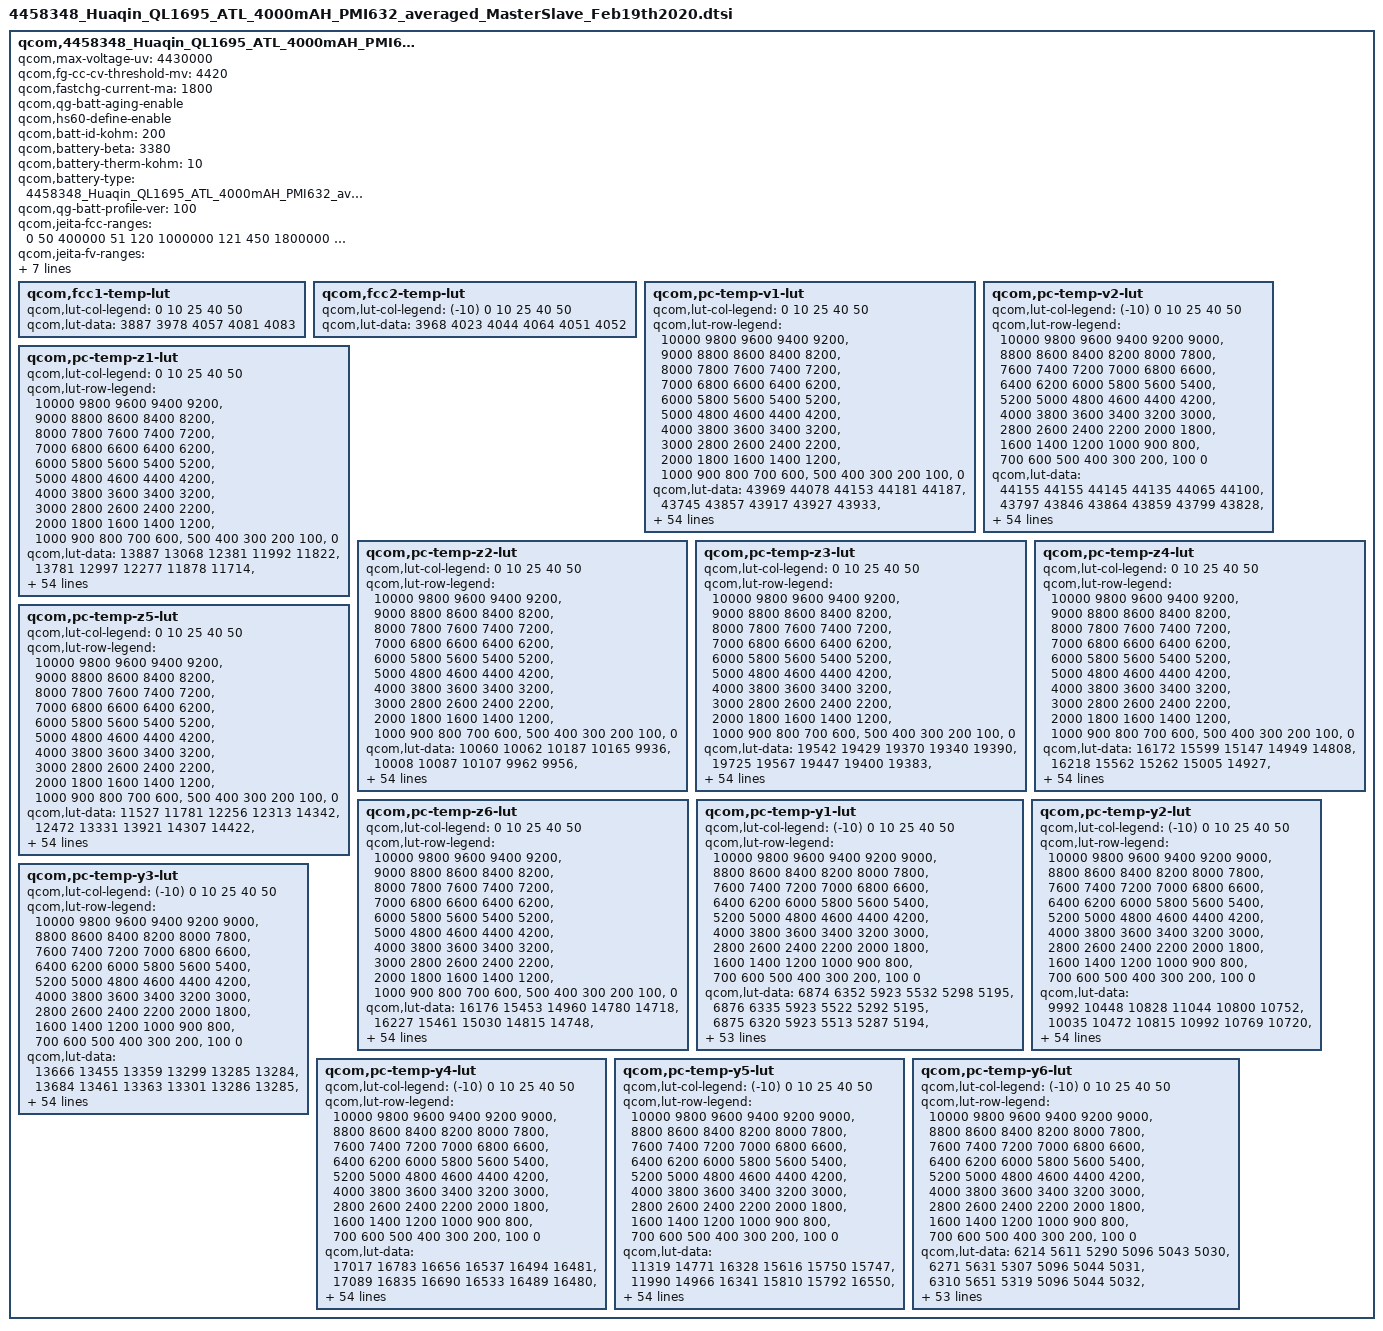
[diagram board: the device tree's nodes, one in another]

qcom,4458348_Huaqin_QL1695_ATL_4000mAH_PMI632 {
    /* 4458348_Huaqin_QL1695_ATL_4000mAH_PMI632_averaged_MasterSlave_Feb19th2020 */
    qcom,max-voltage-uv = <4430000>;
	qcom,fg-cc-cv-threshold-mv = <4420>;
	/* HS60 add for ZQL1693-60 Encrease FCC to 1800mA to trigger TA(5V/1.55A) more ICL by gaochao at 2019/11/05 start */
	qcom,fastchg-current-ma = <1800>;
	/* HS60 add for ZQL1693-60 Encrease FCC to 1800mA to trigger TA(5V/1.55A) more ICL by gaochao at 2019/11/05 end */
	/* HS60 add for SR-ZQL1695-01-357 Import battery aging by gaochao at 2019/08/29 start */
	qcom,qg-batt-aging-enable;
	/* HS60 add for SR-ZQL1695-01-357 Import battery aging by gaochao at 2019/08/29 end */
	/* HS70 add for HS70-135 Distinguish HS60 and HS70 charging by gaochao at 2019/10/03 start */
	qcom,hs60-define-enable;
	/* HS70 add for HS70-135 Distinguish HS60 and HS70 charging by gaochao at 2019/10/03 end */
	qcom,batt-id-kohm = <200>;
	qcom,battery-beta = <3380>;
    qcom,battery-therm-kohm = <10>;
    qcom,battery-type = "4458348_Huaqin_QL1695_ATL_4000mAH_PMI632_averaged_MasterSlave_Feb19th2020";
    qcom,qg-batt-profile-ver = <100>;
	/*HS60 add for ZQL1693-50 by wangzikang at 2019/09/26 start*/
	/*HS60 add for ZQL1693-58 by wangzikang at 2019/10/18 start*/
	/* HS60 add for ZQL1693-60 Encrease FCC to 1800mA to trigger TA(5V/1.55A) more ICL by gaochao at 2019/11/05 start */
	qcom,jeita-fcc-ranges = <0   50  400000
				 51   120   1000000
				 121 450  1800000
				 451 500  1800000>;
	/* HS60 add for ZQL1693-60 Encrease FCC to 1800mA to trigger TA(5V/1.55A) more ICL by gaochao at 2019/11/05 end */
	/*HS60 add for ZQL1693-58 by wangzikang at 2019/10/18 end*/
	qcom,jeita-fv-ranges =  <0   50  4430000
				 51   120  4430000
				 121 450  4430000
				 451 500  4200000>;
	/*HS60 add for ZQL1693-50 by wangzikang at 2019/09/26 end*/
	/* HS60 add for SR-ZQL1695-01-357 Import battery aging by gaochao at 2019/08/29 start */
	qcom,vfloat-ranges = <0 299 4430000
	                      300 399 4410000
                              400 699 4390000
                              700 999 4370000
                              1000 9999 4320000>;

	qcom,vbat-rechg-ranges = <0 299 4360000
                                  300 399 4340000
                                  400 699 4320000
                                  700 999 4300000
                                  1000 9999 4250000>;
	/* HS60 add for SR-ZQL1695-01-357 Import battery aging by gaochao at 2019/08/29 end */

	/* COOL = 15 DegC, WARM = 45 DegC */
	qcom,jeita-soft-thresholds = <0x2554 0xFDC>;
	/* COLD = 0 DegC, HOT = 55 DegC */
	/*HS60 add for ZQL1693-50 by wangzikang at 2019/09/26 start*/
	qcom,jeita-hard-thresholds = <0x36B9 0xDBF>;//0xBEF -->0xDBF
	/*HS60 add for ZQL1693-50 by wangzikang at 2019/09/26 end*/
	qcom,fcc1-temp-lut {
		qcom,lut-col-legend = <0 10 25 40 50>;
		qcom,lut-data = <3887 3978 4057 4081 4083>;
	};

	qcom,fcc2-temp-lut {
		qcom,lut-col-legend = <(-10) 0 10 25 40 50>;
		qcom,lut-data = <3968 4023 4044 4064 4051 4052>;
	};

	qcom,pc-temp-v1-lut {
		qcom,lut-col-legend = <0 10 25 40 50>;
		qcom,lut-row-legend = <10000 9800 9600 9400 9200>,
			<9000 8800 8600 8400 8200>,
			<8000 7800 7600 7400 7200>,
			<7000 6800 6600 6400 6200>,
			<6000 5800 5600 5400 5200>,
			<5000 4800 4600 4400 4200>,
			<4000 3800 3600 3400 3200>,
			<3000 2800 2600 2400 2200>,
			<2000 1800 1600 1400 1200>,
			<1000 900 800 700 600>,
			<500 400 300 200 100>,
			<0>;
		qcom,lut-data = <43969 44078 44153 44181 44187>,
			<43745 43857 43917 43927 43933>,
			<43510 43631 43693 43703 43712>,
			<43270 43403 43470 43484 43497>,
			<43030 43172 43239 43259 43275>,
			<42790 42935 43002 43029 43048>,
			<42551 42692 42762 42795 42817>,
			<42313 42447 42517 42554 42580>,
			<42076 42206 42273 42310 42340>,
			<41846 41967 42033 42069 42103>,
			<41626 41735 41798 41832 41867>,
			<41412 41508 41566 41599 41635>,
			<41203 41287 41338 41372 41407>,
			<41000 41076 41116 41150 41183>,
			<40799 40872 40900 40933 40965>,
			<40597 40672 40693 40723 40754>,
			<40398 40471 40496 40521 40551>,
			<40216 40280 40310 40328 40355>,
			<40048 40113 40133 40145 40169>,
			<39886 39966 39974 39978 39999>,
			<39729 39793 39814 39819 39837>,
			<39574 39550 39613 39630 39648>,
			<39392 39300 39361 39390 39414>,
			<39145 39116 39145 39169 39194>,
			<38921 38964 38986 39000 39022>,
			<38797 38834 38850 38856 38873>,
			<38710 38723 38730 38732 38744>,
			<38632 38624 38625 38624 38633>,
			<38554 38534 38531 38526 38532>,
			<38483 38452 38444 38433 38438>,
			<38420 38382 38367 38349 38351>,
			<38362 38321 38298 38274 38272>,
			<38313 38268 38236 38207 38197>,
			<38271 38223 38183 38146 38129>,
			<38236 38185 38141 38095 38070>,
			<38203 38151 38101 38045 38013>,
			<38178 38124 38059 37989 37946>,
			<38145 38095 38016 37930 37871>,
			<38092 38044 37957 37860 37790>,
			<38013 37950 37870 37777 37705>,
			<37918 37838 37766 37680 37608>,
			<37791 37714 37652 37565 37492>,
			<37650 37571 37519 37431 37355>,
			<37497 37406 37356 37272 37190>,
			<37337 37244 37199 37130 37053>,
			<37213 37131 37091 37040 36971>,
			<37172 37104 37065 37010 36945>,
			<37137 37078 37043 36991 36930>,
			<37107 37055 37027 36976 36911>,
			<37071 37018 36988 36929 36853>,
			<36971 36817 36755 36664 36562>,
			<36586 36369 36315 36221 36113>,
			<36039 35771 35732 35637 35528>,
			<35286 34922 34930 34842 34728>,
			<33997 33524 33676 33598 33474>,
			<30000 30000 30000 30000 30000>;
	};

	qcom,pc-temp-v2-lut {
		qcom,lut-col-legend = <(-10) 0 10 25 40 50>;
		qcom,lut-row-legend = <10000 9800 9600 9400 9200 9000>,
			<8800 8600 8400 8200 8000 7800>,
			<7600 7400 7200 7000 6800 6600>,
			<6400 6200 6000 5800 5600 5400>,
			<5200 5000 4800 4600 4400 4200>,
			<4000 3800 3600 3400 3200 3000>,
			<2800 2600 2400 2200 2000 1800>,
			<1600 1400 1200 1000 900 800>,
			<700 600 500 400 300 200>,
			<100 0>;
		qcom,lut-data = <44155 44155 44145 44135 44065 44100>,
			<43797 43846 43864 43859 43799 43828>,
			<43474 43561 43599 43597 43544 43570>,
			<43196 43303 43351 43354 43305 43331>,
			<42959 43071 43123 43129 43081 43110>,
			<42723 42840 42891 42900 42853 42887>,
			<42463 42597 42649 42661 42616 42652>,
			<42198 42352 42404 42419 42376 42413>,
			<41949 42105 42161 42178 42138 42175>,
			<41710 41857 41919 41937 41900 41937>,
			<41492 41609 41682 41701 41666 41702>,
			<41314 41348 41449 41467 41435 41471>,
			<41148 41100 41221 41239 41209 41244>,
			<40940 40918 41003 41018 40990 41023>,
			<40670 40785 40791 40802 40777 40807>,
			<40375 40622 40585 40595 40571 40600>,
			<40063 40360 40387 40392 40370 40401>,
			<39741 40059 40190 40197 40178 40210>,
			<39474 39810 39986 40018 40000 40031>,
			<39257 39591 39774 39847 39832 39860>,
			<39057 39377 39555 39650 39646 39675>,
			<38850 39160 39314 39408 39423 39460>,
			<38651 38954 39083 39171 39198 39244>,
			<38500 38771 38897 38974 38998 39040>,
			<38384 38607 38736 38796 38812 38844>,
			<38292 38451 38591 38650 38662 38689>,
			<38219 38287 38461 38528 38543 38568>,
			<38159 38148 38344 38420 38439 38462>,
			<38102 38067 38233 38322 38342 38361>,
			<38048 38011 38131 38231 38253 38267>,
			<37995 37963 38039 38146 38174 38184>,
			<37939 37918 37954 38067 38102 38109>,
			<37882 37876 37884 37994 38031 38036>,
			<37822 37831 37837 37929 37962 37965>,
			<37760 37785 37800 37869 37892 37892>,
			<37696 37734 37760 37803 37812 37804>,
			<37630 37677 37721 37734 37720 37692>,
			<37561 37615 37676 37661 37626 37581>,
			<37486 37543 37612 37583 37536 37486>,
			<37402 37462 37532 37500 37446 37395>,
			<37311 37369 37435 37413 37353 37303>,
			<37216 37262 37312 37318 37259 37209>,
			<37115 37139 37177 37191 37135 37083>,
			<37021 36996 37026 37045 36992 36935>,
			<36935 36844 36860 36922 36886 36827>,
			<36855 36733 36760 36868 36847 36794>,
			<36812 36692 36727 36851 36837 36784>,
			<36764 36657 36683 36831 36822 36768>,
			<36716 36616 36630 36799 36789 36734>,
			<36666 36558 36530 36712 36685 36619>,
			<36592 36422 36273 36423 36326 36250>,
			<36442 36075 35778 35904 35793 35720>,
			<36102 35456 35121 35225 35101 35024>,
			<35495 34490 34179 34270 34117 34076>,
			<34575 33032 32590 33047 32788 32701>,
			<33650 30841 27072 27620 27679 27649>;
	};

	qcom,pc-temp-z1-lut {
		qcom,lut-col-legend = <0 10 25 40 50>;
		qcom,lut-row-legend = <10000 9800 9600 9400 9200>,
			<9000 8800 8600 8400 8200>,
			<8000 7800 7600 7400 7200>,
			<7000 6800 6600 6400 6200>,
			<6000 5800 5600 5400 5200>,
			<5000 4800 4600 4400 4200>,
			<4000 3800 3600 3400 3200>,
			<3000 2800 2600 2400 2200>,
			<2000 1800 1600 1400 1200>,
			<1000 900 800 700 600>,
			<500 400 300 200 100>,
			<0>;
		qcom,lut-data = <13887 13068 12381 11992 11822>,
			<13781 12997 12277 11878 11714>,
			<13760 12951 12242 11854 11702>,
			<13750 12936 12224 11840 11697>,
			<13737 12928 12216 11835 11692>,
			<13719 12925 12211 11830 11687>,
			<13707 12920 12205 11825 11683>,
			<13703 12913 12200 11822 11681>,
			<13699 12907 12197 11819 11680>,
			<13697 12902 12194 11817 11679>,
			<13702 12897 12190 11814 11679>,
			<13709 12894 12186 11812 11679>,
			<13711 12892 12179 11810 11679>,
			<13712 12889 12175 11808 11678>,
			<13712 12886 12174 11807 11678>,
			<13710 12884 12174 11807 11678>,
			<13706 12880 12174 11807 11678>,
			<13704 12877 12174 11811 11678>,
			<13704 12877 12175 11815 11678>,
			<13706 12878 12177 11814 11679>,
			<13712 12880 12179 11812 11682>,
			<13722 12889 12183 11812 11685>,
			<13732 12901 12187 11818 11689>,
			<13743 12912 12193 11824 11693>,
			<13752 12924 12199 11828 11696>,
			<13758 12929 12206 11831 11699>,
			<13760 12930 12211 11834 11701>,
			<13761 12931 12216 11836 11705>,
			<13771 12933 12221 11838 11708>,
			<13784 12937 12227 11843 11710>,
			<13787 12940 12233 11849 11712>,
			<13786 12943 12238 11853 11715>,
			<13785 12946 12243 11857 11719>,
			<13785 12947 12247 11860 11723>,
			<13786 12947 12249 11864 11727>,
			<13788 12948 12251 11869 11731>,
			<13802 12954 12255 11874 11736>,
			<13817 12961 12261 11880 11741>,
			<13824 12966 12268 11884 11745>,
			<13833 12970 12278 11888 11747>,
			<13839 12973 12284 11890 11749>,
			<13843 12978 12286 11892 11750>,
			<13848 12982 12287 11894 11752>,
			<13856 12982 12289 11897 11753>,
			<13861 12989 12293 11899 11754>,
			<13870 12991 12289 11898 11756>,
			<13860 12986 12296 11896 11751>,
			<13868 12986 12297 11897 11753>,
			<13868 12988 12299 11900 11752>,
			<13863 13002 12304 11903 11758>,
			<13879 13017 12315 11909 11767>,
			<13901 13024 12332 11920 11772>,
			<13937 13057 12346 11936 11784>,
			<13972 13095 12372 11956 11802>,
			<13972 13095 12372 11956 11802>,
			<13972 13095 12372 11956 11802>;
	};

	qcom,pc-temp-z2-lut {
		qcom,lut-col-legend = <0 10 25 40 50>;
		qcom,lut-row-legend = <10000 9800 9600 9400 9200>,
			<9000 8800 8600 8400 8200>,
			<8000 7800 7600 7400 7200>,
			<7000 6800 6600 6400 6200>,
			<6000 5800 5600 5400 5200>,
			<5000 4800 4600 4400 4200>,
			<4000 3800 3600 3400 3200>,
			<3000 2800 2600 2400 2200>,
			<2000 1800 1600 1400 1200>,
			<1000 900 800 700 600>,
			<500 400 300 200 100>,
			<0>;
		qcom,lut-data = <10060 10062 10187 10165 9936>,
			<10008 10087 10107 9962 9956>,
			<9981 10102 10156 10012 9979>,
			<9959 10109 10201 10078 9998>,
			<9954 10119 10201 10081 9991>,
			<9960 10126 10196 10042 9950>,
			<9968 10131 10194 10011 9928>,
			<9977 10136 10195 10018 9933>,
			<9987 10139 10195 10038 9945>,
			<10001 10142 10190 10031 9959>,
			<10054 10146 10181 9995 9979>,
			<10118 10155 10178 9979 9988>,
			<10134 10163 10179 9988 9976>,
			<10138 10164 10180 9999 9961>,
			<10139 10159 10177 10005 9960>,
			<10140 10157 10172 10010 9960>,
			<10142 10156 10169 10014 9959>,
			<10140 10153 10166 10016 9956>,
			<10113 10152 10165 10015 9953>,
			<10084 10155 10170 10014 9955>,
			<10072 10151 10177 10015 9961>,
			<10061 10117 10181 10029 9964>,
			<10042 10074 10182 10067 9969>,
			<9994 10057 10179 10092 9972>,
			<9953 10046 10155 10050 9957>,
			<9957 10042 10128 9979 9933>,
			<9975 10043 10127 9960 9926>,
			<9982 10047 10139 9957 9929>,
			<9974 10056 10150 9959 9933>,
			<9964 10077 10166 9997 9936>,
			<9965 10091 10180 10047 9941>,
			<9974 10096 10181 10051 9957>,
			<9986 10101 10177 10034 10000>,
			<10000 10107 10177 10026 10026>,
			<10015 10119 10188 10043 10031>,
			<10027 10129 10204 10069 10037>,
			<10035 10139 10223 10093 10062>,
			<10043 10149 10247 10127 10107>,
			<10055 10161 10271 10154 10124>,
			<10069 10178 10303 10179 10119>,
			<10072 10187 10322 10198 10114>,
			<10064 10184 10317 10203 10112>,
			<10047 10182 10307 10202 10111>,
			<9930 10186 10304 10180 10123>,
			<9832 10195 10321 10174 10116>,
			<11563 10206 10316 10162 10092>,
			<10253 10277 10288 10194 10094>,
			<10569 10327 10275 10166 10093>,
			<11750 10408 10313 10188 10086>,
			<10223 10400 10373 10202 10158>,
			<10203 10401 10335 10038 9967>,
			<9872 10377 10307 9999 9911>,
			<9759 10253 10234 9974 9838>,
			<9411 10036 10175 9919 9798>,
			<9411 10036 10175 9919 9798>,
			<9411 10036 10175 9919 9798>;
	};

	qcom,pc-temp-z3-lut {
		qcom,lut-col-legend = <0 10 25 40 50>;
		qcom,lut-row-legend = <10000 9800 9600 9400 9200>,
			<9000 8800 8600 8400 8200>,
			<8000 7800 7600 7400 7200>,
			<7000 6800 6600 6400 6200>,
			<6000 5800 5600 5400 5200>,
			<5000 4800 4600 4400 4200>,
			<4000 3800 3600 3400 3200>,
			<3000 2800 2600 2400 2200>,
			<2000 1800 1600 1400 1200>,
			<1000 900 800 700 600>,
			<500 400 300 200 100>,
			<0>;
		qcom,lut-data = <19542 19429 19370 19340 19390>,
			<19725 19567 19447 19400 19383>,
			<19835 19648 19473 19412 19394>,
			<19915 19650 19485 19418 19400>,
			<19933 19643 19482 19417 19402>,
			<19912 19637 19475 19409 19403>,
			<19883 19628 19471 19406 19403>,
			<19865 19618 19470 19407 19401>,
			<19852 19613 19467 19409 19398>,
			<19834 19609 19459 19408 19395>,
			<19798 19605 19447 19404 19390>,
			<19760 19596 19442 19400 19387>,
			<19745 19588 19439 19393 19385>,
			<19733 19583 19438 19386 19383>,
			<19728 19580 19439 19384 19381>,
			<19736 19578 19440 19384 19378>,
			<19747 19579 19437 19384 19377>,
			<19745 19579 19421 19384 19377>,
			<19729 19576 19410 19383 19378>,
			<19720 19565 19414 19383 19376>,
			<19730 19562 19422 19382 19373>,
			<19747 19595 19438 19386 19375>,
			<19767 19633 19473 19415 19400>,
			<19809 19639 19490 19436 19419>,
			<19842 19639 19488 19433 19418>,
			<19843 19638 19485 19426 19416>,
			<19837 19632 19483 19420 19413>,
			<19832 19624 19482 19415 19408>,
			<19828 19621 19480 19411 19402>,
			<19825 19620 19477 19409 19393>,
			<19821 19617 19472 19408 19383>,
			<19815 19611 19467 19403 19380>,
			<19808 19603 19463 19390 19379>,
			<19797 19597 19457 19382 19378>,
			<19784 19592 19447 19378 19372>,
			<19776 19586 19438 19377 19365>,
			<19770 19578 19437 19377 19364>,
			<19763 19570 19437 19378 19363>,
			<19752 19563 19437 19379 19363>,
			<19738 19556 19434 19379 19363>,
			<19731 19553 19429 19378 19363>,
			<19729 19553 19422 19379 19364>,
			<19711 19554 19415 19381 19365>,
			<19507 19529 19414 19387 19379>,
			<19321 19519 19414 19387 19383>,
			<19260 19512 19409 19369 19375>,
			<19261 19461 19395 19373 19370>,
			<19261 19437 19392 19369 19349>,
			<19261 19383 19364 19347 19342>,
			<19261 19380 19359 19347 19341>,
			<19261 19385 19387 19390 19381>,
			<19264 19382 19401 19395 19388>,
			<19265 19389 19397 19401 19392>,
			<19284 19535 19406 19385 19388>,
			<19284 19535 19406 19385 19388>,
			<19284 19535 19406 19385 19388>;
	};

	qcom,pc-temp-z4-lut {
		qcom,lut-col-legend = <0 10 25 40 50>;
		qcom,lut-row-legend = <10000 9800 9600 9400 9200>,
			<9000 8800 8600 8400 8200>,
			<8000 7800 7600 7400 7200>,
			<7000 6800 6600 6400 6200>,
			<6000 5800 5600 5400 5200>,
			<5000 4800 4600 4400 4200>,
			<4000 3800 3600 3400 3200>,
			<3000 2800 2600 2400 2200>,
			<2000 1800 1600 1400 1200>,
			<1000 900 800 700 600>,
			<500 400 300 200 100>,
			<0>;
		qcom,lut-data = <16172 15599 15147 14949 14808>,
			<16218 15562 15262 15005 14927>,
			<16115 15498 15166 14975 14910>,
			<15859 15393 15059 14924 14877>,
			<15653 15242 15020 14903 14864>,
			<15495 15151 14996 14894 14858>,
			<15374 15110 14975 14885 14852>,
			<15306 15081 14955 14873 14846>,
			<15259 15054 14938 14861 14840>,
			<15227 15030 14925 14853 14833>,
			<15205 15011 14913 14846 14826>,
			<15188 14995 14901 14838 14819>,
			<15171 14981 14888 14830 14811>,
			<15148 14966 14875 14821 14803>,
			<15133 14952 14860 14811 14795>,
			<15133 14947 14846 14801 14788>,
			<15134 14948 14841 14791 14780>,
			<15125 14950 14839 14780 14771>,
			<15082 14941 14837 14772 14763>,
			<15048 14914 14827 14765 14756>,
			<15047 14906 14816 14760 14750>,
			<15048 15079 14851 14770 14758>,
			<15067 15283 15006 14863 14831>,
			<15280 15283 15089 14931 14886>,
			<15491 15199 15056 14922 14878>,
			<15471 15125 15004 14902 14860>,
			<15352 15074 14973 14888 14849>,
			<15254 15035 14949 14876 14840>,
			<15192 15012 14931 14865 14833>,
			<15145 14996 14917 14852 14829>,
			<15121 14989 14905 14841 14824>,
			<15107 14988 14898 14832 14817>,
			<15096 14987 14892 14826 14806>,
			<15087 14986 14885 14819 14795>,
			<15080 14982 14873 14805 14783>,
			<15071 14976 14864 14794 14774>,
			<15059 14962 14865 14799 14781>,
			<15046 14945 14870 14816 14805>,
			<15036 14940 14875 14827 14814>,
			<15025 14938 14886 14831 14811>,
			<15009 14935 14894 14833 14807>,
			<14982 14914 14879 14828 14804>,
			<14983 14891 14856 14818 14802>,
			<15149 14885 14856 14833 14829>,
			<15290 14862 14847 14835 14836>,
			<15327 14832 14822 14804 14782>,
			<15305 14846 14802 14782 14760>,
			<15290 14846 14770 14757 14745>,
			<15275 14888 14753 14732 14714>,
			<15262 14880 14744 14720 14712>,
			<15255 14895 14765 14749 14757>,
			<15288 14911 14756 14753 14757>,
			<15313 14917 14761 14748 14754>,
			<15374 14833 14757 14755 14748>,
			<15374 14833 14757 14755 14748>,
			<15374 14833 14757 14755 14748>;
	};

	qcom,pc-temp-z5-lut {
		qcom,lut-col-legend = <0 10 25 40 50>;
		qcom,lut-row-legend = <10000 9800 9600 9400 9200>,
			<9000 8800 8600 8400 8200>,
			<8000 7800 7600 7400 7200>,
			<7000 6800 6600 6400 6200>,
			<6000 5800 5600 5400 5200>,
			<5000 4800 4600 4400 4200>,
			<4000 3800 3600 3400 3200>,
			<3000 2800 2600 2400 2200>,
			<2000 1800 1600 1400 1200>,
			<1000 900 800 700 600>,
			<500 400 300 200 100>,
			<0>;
		qcom,lut-data = <11527 11781 12256 12313 14342>,
			<12472 13331 13921 14307 14422>,
			<13248 14417 15015 15288 15535>,
			<13918 14937 15638 15975 16328>,
			<14347 15277 15631 16007 16652>,
			<14625 15420 15569 15660 16836>,
			<14822 15479 15567 15502 16913>,
			<14962 15533 15718 15758 16874>,
			<15073 15652 15842 16095 16810>,
			<15104 15849 15647 16196 16739>,
			<14752 15940 15266 16155 16501>,
			<14257 15891 15178 16032 16384>,
			<14117 15833 15261 15636 16347>,
			<14089 15880 15394 15279 16320>,
			<14099 16003 15717 15305 16337>,
			<14361 16095 16116 15456 16358>,
			<14734 16153 16046 15634 16451>,
			<14787 16186 15286 15926 16835>,
			<14811 16264 14816 16269 17243>,
			<15064 16618 15514 16636 17470>,
			<15768 17017 16504 16997 17636>,
			<16788 18032 16607 17037 17545>,
			<17524 19035 16376 16652 16855>,
			<18314 18579 16110 16155 16189>,
			<18881 16674 15718 15599 15891>,
			<18408 15734 15362 15068 15674>,
			<16934 16085 15489 14998 15578>,
			<16246 16720 16150 15149 15684>,
			<16514 17422 16805 15365 15773>,
			<16993 18315 17349 15830 15558>,
			<17498 18930 17869 16318 15267>,
			<18183 19238 18413 16278 15361>,
			<18650 19451 18978 15879 15820>,
			<18803 19597 19158 15692 16231>,
			<18867 19716 19025 16124 16612>,
			<18884 19760 18898 16787 16943>,
			<18971 19426 19167 17315 17075>,
			<19021 18978 19821 17833 17155>,
			<18890 18937 20014 17988 17168>,
			<18659 19076 19710 17807 17038>,
			<18551 19267 19310 17632 16938>,
			<18644 19709 18781 17725 16995>,
			<18348 20013 18080 17905 17103>,
			<14179 17744 17577 17804 18033>,
			<11413 17340 17624 17314 18096>,
			<10784 17272 17444 15745 17189>,
			<10738 14361 16364 16143 16653>,
			<10716 13618 16899 16506 14974>,
			<10705 12339 14951 15730 15976>,
			<10703 12350 14950 16323 16744>,
			<10722 12422 15512 17611 17309>,
			<10715 12202 16128 17042 16773>,
			<10671 12315 15350 16783 16168>,
			<10760 17280 15390 14457 14599>,
			<10760 17280 15390 14457 14599>,
			<10760 17280 15390 14457 14599>;
	};

	qcom,pc-temp-z6-lut {
		qcom,lut-col-legend = <0 10 25 40 50>;
		qcom,lut-row-legend = <10000 9800 9600 9400 9200>,
			<9000 8800 8600 8400 8200>,
			<8000 7800 7600 7400 7200>,
			<7000 6800 6600 6400 6200>,
			<6000 5800 5600 5400 5200>,
			<5000 4800 4600 4400 4200>,
			<4000 3800 3600 3400 3200>,
			<3000 2800 2600 2400 2200>,
			<2000 1800 1600 1400 1200>,
			<1000 900 800 700 600>,
			<500 400 300 200 100>,
			<0>;
		qcom,lut-data = <16176 15453 14960 14780 14718>,
			<16227 15461 15030 14815 14748>,
			<16186 15455 14993 14804 14743>,
			<16078 15417 14950 14784 14731>,
			<15976 15329 14928 14772 14725>,
			<15876 15268 14913 14764 14722>,
			<15791 15239 14900 14757 14719>,
			<15743 15217 14890 14752 14715>,
			<15710 15197 14880 14747 14710>,
			<15679 15181 14868 14742 14706>,
			<15648 15166 14856 14737 14700>,
			<15620 15152 14846 14731 14696>,
			<15599 15140 14838 14723 14691>,
			<15580 15129 14832 14716 14686>,
			<15572 15119 14826 14710 14681>,
			<15575 15116 14821 14705 14676>,
			<15580 15116 14814 14701 14672>,
			<15577 15116 14805 14697 14669>,
			<15553 15111 14800 14693 14665>,
			<15535 15096 14800 14690 14661>,
			<15540 15092 14800 14687 14658>,
			<15556 15186 14821 14694 14663>,
			<15587 15297 14910 14752 14710>,
			<15707 15302 14957 14795 14746>,
			<15816 15272 14942 14790 14742>,
			<15810 15243 14920 14778 14734>,
			<15765 15219 14907 14769 14727>,
			<15728 15200 14897 14761 14721>,
			<15704 15192 14889 14754 14715>,
			<15686 15187 14881 14749 14708>,
			<15678 15184 14875 14743 14701>,
			<15672 15181 14870 14736 14696>,
			<15667 15179 14866 14728 14691>,
			<15660 15177 14861 14720 14686>,
			<15653 15175 14851 14713 14677>,
			<15650 15172 14844 14707 14670>,
			<15648 15166 14845 14710 14673>,
			<15646 15159 14849 14718 14683>,
			<15645 15157 14851 14723 14687>,
			<15643 15157 14856 14726 14686>,
			<15641 15156 14860 14727 14685>,
			<15640 15153 14851 14726 14685>,
			<15636 15147 14838 14723 14684>,
			<15618 15137 14840 14732 14703>,
			<15602 15127 14837 14734 14709>,
			<15596 15114 14825 14712 14681>,
			<15592 15096 14809 14704 14670>,
			<15588 15086 14795 14691 14652>,
			<15586 15078 14774 14668 14634>,
			<15587 15079 14770 14664 14634>,
			<15597 15097 14796 14701 14676>,
			<15629 15111 14804 14708 14683>,
			<15663 15131 14808 14713 14687>,
			<15741 15193 14818 14712 14687>,
			<15741 15193 14818 14712 14687>,
			<15741 15193 14818 14712 14687>;
	};

	qcom,pc-temp-y1-lut {
		qcom,lut-col-legend = <(-10) 0 10 25 40 50>;
		qcom,lut-row-legend = <10000 9800 9600 9400 9200 9000>,
			<8800 8600 8400 8200 8000 7800>,
			<7600 7400 7200 7000 6800 6600>,
			<6400 6200 6000 5800 5600 5400>,
			<5200 5000 4800 4600 4400 4200>,
			<4000 3800 3600 3400 3200 3000>,
			<2800 2600 2400 2200 2000 1800>,
			<1600 1400 1200 1000 900 800>,
			<700 600 500 400 300 200>,
			<100 0>;
		qcom,lut-data = <6874 6352 5923 5532 5298 5195>,
			<6876 6335 5923 5522 5292 5195>,
			<6875 6320 5923 5513 5287 5194>,
			<6874 6308 5922 5504 5282 5193>,
			<6873 6300 5920 5497 5278 5192>,
			<6872 6296 5918 5491 5275 5190>,
			<6872 6299 5916 5486 5272 5189>,
			<6871 6304 5912 5482 5270 5187>,
			<6871 6303 5908 5479 5268 5186>,
			<6867 6300 5900 5476 5265 5186>,
			<6865 6298 5896 5473 5263 5186>,
			<6869 6300 5897 5471 5262 5185>,
			<6876 6302 5898 5469 5261 5184>,
			<6879 6305 5897 5468 5261 5184>,
			<6879 6311 5895 5468 5259 5185>,
			<6879 6316 5893 5468 5259 5185>,
			<6882 6317 5894 5467 5259 5186>,
			<6888 6318 5894 5466 5260 5187>,
			<6890 6317 5894 5466 5260 5187>,
			<6887 6314 5894 5467 5261 5188>,
			<6883 6312 5895 5468 5261 5189>,
			<6883 6316 5897 5471 5262 5190>,
			<6885 6320 5899 5473 5264 5190>,
			<6884 6321 5900 5476 5267 5191>,
			<6876 6320 5900 5479 5270 5192>,
			<6868 6319 5901 5482 5271 5193>,
			<6865 6319 5905 5485 5271 5195>,
			<6863 6319 5910 5489 5272 5197>,
			<6860 6318 5914 5492 5274 5199>,
			<6857 6317 5918 5495 5277 5201>,
			<6855 6315 5919 5499 5281 5203>,
			<6855 6312 5915 5506 5285 5206>,
			<6859 6310 5912 5511 5288 5209>,
			<6860 6309 5913 5514 5291 5211>,
			<6855 6310 5916 5516 5293 5213>,
			<6851 6310 5919 5519 5295 5214>,
			<6850 6309 5925 5525 5296 5215>,
			<6849 6309 5929 5528 5297 5216>,
			<6848 6308 5932 5529 5298 5217>,
			<6847 6307 5934 5529 5299 5218>,
			<6846 6307 5936 5532 5300 5219>,
			<6843 6308 5936 5540 5302 5221>,
			<6839 6310 5938 5543 5305 5222>,
			<6840 6314 5944 5548 5308 5223>,
			<6841 6324 5947 5559 5311 5227>,
			<6840 6356 5966 5565 5316 5230>,
			<6886 6358 5967 5567 5315 5230>,
			<6900 6349 5961 5567 5314 5229>,
			<6913 6348 5972 5571 5315 5231>,
			<6933 6375 5971 5570 5315 5232>,
			<6948 6391 5980 5573 5319 5233>,
			<6977 6427 5994 5586 5326 5242>,
			<7066 6510 6050 5609 5337 5249>,
			<7203 6528 6109 5638 5349 5261>,
			<7203 6528 6109 5638 5349 5261>,
			<7203 6528 6109 5638 5349 5261>;
	};

	qcom,pc-temp-y2-lut {
		qcom,lut-col-legend = <(-10) 0 10 25 40 50>;
		qcom,lut-row-legend = <10000 9800 9600 9400 9200 9000>,
			<8800 8600 8400 8200 8000 7800>,
			<7600 7400 7200 7000 6800 6600>,
			<6400 6200 6000 5800 5600 5400>,
			<5200 5000 4800 4600 4400 4200>,
			<4000 3800 3600 3400 3200 3000>,
			<2800 2600 2400 2200 2000 1800>,
			<1600 1400 1200 1000 900 800>,
			<700 600 500 400 300 200>,
			<100 0>;
		qcom,lut-data = <9992 10448 10828 11044 10800 10752>,
			<10035 10472 10815 10992 10769 10720>,
			<10100 10503 10800 10939 10728 10686>,
			<10172 10533 10783 10888 10685 10654>,
			<10232 10556 10766 10845 10649 10625>,
			<10263 10565 10748 10814 10628 10600>,
			<10270 10562 10729 10791 10616 10574>,
			<10274 10556 10711 10774 10607 10554>,
			<10306 10549 10694 10762 10599 10547>,
			<10460 10538 10678 10753 10584 10544>,
			<10571 10533 10671 10747 10577 10540>,
			<10527 10586 10676 10740 10581 10526>,
			<10445 10660 10686 10737 10588 10511>,
			<10433 10664 10708 10742 10600 10507>,
			<10502 10638 10756 10756 10621 10506>,
			<10556 10624 10797 10776 10642 10509>,
			<10314 10671 10823 10814 10656 10548>,
			<9830 10735 10848 10865 10675 10600>,
			<9685 10750 10878 10933 10717 10632>,
			<9680 10754 10911 11013 10792 10660>,
			<9677 10755 10921 11032 10851 10692>,
			<9674 10751 10894 10995 10902 10757>,
			<9671 10744 10867 10963 10933 10809>,
			<9669 10732 10875 10966 10903 10795>,
			<9667 10710 10900 10973 10831 10755>,
			<9666 10699 10910 10976 10810 10748>,
			<9665 10698 10912 10974 10828 10774>,
			<9664 10697 10912 10973 10849 10806>,
			<9663 10687 10905 10994 10882 10828>,
			<9662 10644 10887 11032 10937 10848>,
			<9661 10566 10882 11056 10955 10864>,
			<9660 10210 10888 11074 10957 10879>,
			<9660 9827 10892 11084 10959 10896>,
			<9659 9743 10884 11083 10971 10928>,
			<9659 9708 10862 11079 10990 10967>,
			<9658 9690 10837 11078 10989 10981>,
			<9658 9678 10806 11073 10974 10967>,
			<9658 9671 10767 11066 10958 10949>,
			<9658 9666 10711 11034 10948 10908>,
			<9658 9663 10636 10999 10938 10850>,
			<9658 9661 10553 10998 10928 10833>,
			<9658 9659 10457 11007 10916 10842>,
			<9657 9658 10374 10982 10894 10839>,
			<9657 9657 10282 10934 10859 10804>,
			<9657 9656 9834 10908 10809 10699>,
			<9656 9656 9749 10865 10724 10588>,
			<9656 9655 9707 10858 10750 10588>,
			<9655 9655 9688 10856 10760 10597>,
			<9654 9654 9673 10868 10782 10634>,
			<9653 9654 9666 10875 10737 10629>,
			<9651 9653 9660 10828 10660 10561>,
			<9649 9650 9656 10749 10594 10490>,
			<9648 9648 9653 10656 10592 10415>,
			<9647 9648 9650 10559 10483 10329>,
			<9647 9648 9650 10559 10483 10329>,
			<9647 9648 9650 10559 10483 10329>;
	};

	qcom,pc-temp-y3-lut {
		qcom,lut-col-legend = <(-10) 0 10 25 40 50>;
		qcom,lut-row-legend = <10000 9800 9600 9400 9200 9000>,
			<8800 8600 8400 8200 8000 7800>,
			<7600 7400 7200 7000 6800 6600>,
			<6400 6200 6000 5800 5600 5400>,
			<5200 5000 4800 4600 4400 4200>,
			<4000 3800 3600 3400 3200 3000>,
			<2800 2600 2400 2200 2000 1800>,
			<1600 1400 1200 1000 900 800>,
			<700 600 500 400 300 200>,
			<100 0>;
		qcom,lut-data = <13666 13455 13359 13299 13285 13284>,
			<13684 13461 13363 13301 13286 13285>,
			<13694 13467 13367 13304 13288 13287>,
			<13700 13472 13371 13306 13290 13288>,
			<13702 13477 13374 13308 13291 13289>,
			<13702 13481 13377 13309 13292 13290>,
			<13694 13485 13379 13310 13293 13291>,
			<13678 13488 13381 13310 13294 13292>,
			<13673 13488 13382 13311 13295 13292>,
			<13677 13483 13385 13311 13296 13293>,
			<13678 13477 13386 13312 13297 13293>,
			<13640 13466 13386 13312 13297 13294>,
			<13577 13455 13387 13312 13298 13294>,
			<13563 13448 13385 13313 13300 13295>,
			<13572 13442 13379 13317 13304 13295>,
			<13580 13439 13375 13319 13306 13296>,
			<13576 13438 13373 13318 13305 13299>,
			<13569 13437 13372 13317 13304 13302>,
			<13563 13434 13370 13318 13305 13303>,
			<13559 13425 13367 13318 13308 13304>,
			<13554 13416 13363 13318 13309 13305>,
			<13547 13408 13357 13315 13305 13301>,
			<13539 13401 13350 13310 13299 13297>,
			<13535 13394 13346 13306 13295 13292>,
			<13536 13389 13344 13302 13290 13287>,
			<13540 13381 13342 13300 13288 13286>,
			<13555 13365 13340 13299 13287 13286>,
			<13590 13351 13338 13299 13286 13286>,
			<13629 13348 13336 13299 13286 13286>,
			<13675 13349 13334 13300 13286 13284>,
			<13726 13352 13333 13300 13287 13283>,
			<13778 13363 13330 13299 13287 13283>,
			<13833 13378 13329 13299 13288 13284>,
			<13891 13396 13330 13299 13288 13285>,
			<13956 13421 13333 13300 13288 13287>,
			<14021 13451 13336 13300 13288 13287>,
			<14082 13485 13341 13300 13287 13285>,
			<14141 13527 13345 13299 13287 13285>,
			<14194 13583 13349 13299 13287 13285>,
			<14245 13656 13352 13298 13288 13286>,
			<14289 13738 13357 13299 13289 13288>,
			<14321 13831 13363 13302 13290 13289>,
			<14349 13937 13371 13301 13289 13288>,
			<14393 14061 13382 13299 13287 13284>,
			<14462 14192 13394 13301 13288 13282>,
			<14557 14246 13410 13304 13293 13292>,
			<14601 14355 13448 13308 13299 13296>,
			<14722 14473 13485 13314 13302 13299>,
			<14909 14599 13560 13321 13305 13299>,
			<15228 14776 13674 13324 13304 13298>,
			<16062 15110 13837 13321 13297 13294>,
			<19169 16488 14199 13322 13297 13294>,
			<27782 22928 14984 13333 13307 13300>,
			<65535 59535 17547 13353 13316 13312>,
			<65535 59535 17547 13353 13316 13312>,
			<65535 59535 17547 13353 13316 13312>;
	};

	qcom,pc-temp-y4-lut {
		qcom,lut-col-legend = <(-10) 0 10 25 40 50>;
		qcom,lut-row-legend = <10000 9800 9600 9400 9200 9000>,
			<8800 8600 8400 8200 8000 7800>,
			<7600 7400 7200 7000 6800 6600>,
			<6400 6200 6000 5800 5600 5400>,
			<5200 5000 4800 4600 4400 4200>,
			<4000 3800 3600 3400 3200 3000>,
			<2800 2600 2400 2200 2000 1800>,
			<1600 1400 1200 1000 900 800>,
			<700 600 500 400 300 200>,
			<100 0>;
		qcom,lut-data = <17017 16783 16656 16537 16494 16481>,
			<17089 16835 16690 16533 16489 16480>,
			<17214 16925 16729 16531 16487 16480>,
			<17353 17024 16766 16529 16485 16479>,
			<17466 17104 16793 16529 16485 16479>,
			<17516 17136 16803 16529 16484 16479>,
			<17512 17130 16798 16529 16485 16479>,
			<17502 17122 16788 16531 16487 16479>,
			<17485 17121 16782 16534 16489 16479>,
			<17447 17122 16777 16539 16491 16481>,
			<17421 17123 16775 16545 16495 16483>,
			<17523 17131 16779 16553 16500 16487>,
			<17710 17150 16786 16562 16506 16491>,
			<17738 17201 16805 16571 16510 16495>,
			<17572 17324 16849 16579 16513 16501>,
			<17389 17387 16883 16591 16517 16506>,
			<17290 17281 16907 16612 16529 16510>,
			<17211 17121 16922 16638 16545 16514>,
			<17142 17046 16915 16673 16567 16526>,
			<17083 17004 16885 16712 16596 16548>,
			<17026 16958 16844 16718 16604 16557>,
			<16952 16897 16770 16663 16590 16556>,
			<16877 16834 16697 16598 16566 16553>,
			<16857 16783 16660 16555 16536 16533>,
			<16861 16738 16634 16521 16498 16494>,
			<16865 16697 16617 16514 16488 16482>,
			<16867 16651 16606 16516 16490 16483>,
			<16868 16617 16597 16519 16495 16483>,
			<16868 16617 16585 16524 16501 16488>,
			<16866 16629 16573 16531 16511 16499>,
			<16865 16645 16560 16538 16522 16510>,
			<16869 16677 16542 16545 16536 16522>,
			<16879 16714 16531 16552 16546 16532>,
			<16887 16738 16537 16559 16551 16540>,
			<16894 16758 16555 16564 16554 16546>,
			<16899 16776 16576 16561 16552 16543>,
			<16902 16795 16603 16547 16534 16522>,
			<16905 16811 16632 16534 16517 16506>,
			<16906 16819 16658 16525 16508 16504>,
			<16904 16825 16681 16518 16501 16503>,
			<16900 16831 16692 16522 16502 16506>,
			<16896 16839 16697 16531 16508 16515>,
			<16892 16842 16700 16531 16504 16509>,
			<16896 16831 16701 16526 16483 16481>,
			<16904 16821 16717 16509 16466 16462>,
			<16903 16790 16717 16516 16483 16487>,
			<16884 16808 16746 16536 16511 16528>,
			<16901 16835 16787 16566 16556 16575>,
			<16924 16874 16846 16618 16600 16616>,
			<16950 16923 16917 16646 16605 16610>,
			<17023 16951 16968 16602 16509 16507>,
			<17526 17073 16991 16579 16499 16498>,
			<19793 18823 17090 16614 16507 16503>,
			<36007 48657 17972 16690 16557 16550>,
			<36007 48657 17972 16690 16557 16550>,
			<36007 48657 17972 16690 16557 16550>;
	};

	qcom,pc-temp-y5-lut {
		qcom,lut-col-legend = <(-10) 0 10 25 40 50>;
		qcom,lut-row-legend = <10000 9800 9600 9400 9200 9000>,
			<8800 8600 8400 8200 8000 7800>,
			<7600 7400 7200 7000 6800 6600>,
			<6400 6200 6000 5800 5600 5400>,
			<5200 5000 4800 4600 4400 4200>,
			<4000 3800 3600 3400 3200 3000>,
			<2800 2600 2400 2200 2000 1800>,
			<1600 1400 1200 1000 900 800>,
			<700 600 500 400 300 200>,
			<100 0>;
		qcom,lut-data = <11319 14771 16328 15616 15750 15747>,
			<11990 14966 16341 15810 15792 16550>,
			<13027 15164 16364 15889 15812 17032>,
			<14153 15363 16388 15878 15814 17268>,
			<15096 15562 16408 15801 15800 17336>,
			<15579 15761 16416 15683 15774 17308>,
			<15663 16009 16424 15353 15516 17081>,
			<15707 16219 16423 14890 15119 16702>,
			<15921 16184 16360 14534 14889 16360>,
			<16818 15811 16179 14213 14737 16002>,
			<17457 15308 15959 13892 14554 15663>,
			<17127 14442 15715 13483 14206 15264>,
			<16518 13591 15401 13175 13907 14849>,
			<16703 13789 14877 13186 14027 14489>,
			<19283 15232 14082 13312 14504 14127>,
			<21332 16502 13777 13345 14690 14014>,
			<19404 17170 14498 13178 14090 14355>,
			<15507 17727 15708 13020 13447 14717>,
			<14399 18339 17010 13304 13470 14662>,
			<14515 18987 18542 14250 13754 14443>,
			<14614 19394 19287 15492 14303 14464>,
			<14248 19567 19484 17754 16490 16012>,
			<13317 19698 19631 19342 18412 17483>,
			<12580 19923 19875 19012 18144 17394>,
			<11919 20277 20155 18160 17165 16987>,
			<11503 20368 20276 17565 16354 16673>,
			<11499 17459 20296 17103 15640 16418>,
			<11571 13847 20317 16874 15151 16081>,
			<11650 13123 20430 17164 14983 15322>,
			<11858 12946 20625 17670 14889 14330>,
			<12072 12793 20578 17794 14928 14095>,
			<12155 12598 19458 17800 15238 14201>,
			<12209 12475 18392 17818 15632 14384>,
			<12268 12544 18165 18419 16026 15072>,
			<12333 12785 18025 19375 16514 16196>,
			<12409 12964 17907 19821 17068 16780>,
			<12540 13080 17816 20097 17784 17064>,
			<12731 13181 17696 20183 18250 17354>,
			<12821 13270 17320 19159 18400 17935>,
			<12808 13349 16765 17844 18492 18547>,
			<12752 13361 16472 17677 18414 18723>,
			<12588 13181 16287 17785 18083 18793>,
			<12278 13067 16285 17129 18055 18804>,
			<12089 13070 16317 16385 18178 18654>,
			<11996 12716 13982 17308 17631 15774>,
			<12100 12670 13274 16581 16196 16615>,
			<12106 12617 13264 16316 16922 15669>,
			<12028 12664 12981 16381 16021 14820>,
			<12079 12650 13199 16520 15503 14283>,
			<12316 12739 13500 16636 15372 14235>,
			<12288 12757 13244 17286 15774 15160>,
			<10968 11931 12718 17671 15961 15073>,
			<9607 9950 12380 17653 19048 15873>,
			<8954 8935 10712 18680 21590 20768>,
			<8954 8935 10712 18680 21590 20768>,
			<8954 8935 10712 18680 21590 20768>;
	};

	qcom,pc-temp-y6-lut {
		qcom,lut-col-legend = <(-10) 0 10 25 40 50>;
		qcom,lut-row-legend = <10000 9800 9600 9400 9200 9000>,
			<8800 8600 8400 8200 8000 7800>,
			<7600 7400 7200 7000 6800 6600>,
			<6400 6200 6000 5800 5600 5400>,
			<5200 5000 4800 4600 4400 4200>,
			<4000 3800 3600 3400 3200 3000>,
			<2800 2600 2400 2200 2000 1800>,
			<1600 1400 1200 1000 900 800>,
			<700 600 500 400 300 200>,
			<100 0>;
		qcom,lut-data = <6214 5611 5290 5096 5043 5030>,
			<6271 5631 5307 5096 5044 5031>,
			<6310 5651 5319 5096 5044 5032>,
			<6333 5669 5328 5096 5045 5033>,
			<6345 5682 5333 5096 5045 5034>,
			<6349 5686 5335 5096 5046 5035>,
			<6337 5683 5331 5097 5047 5035>,
			<6315 5677 5325 5097 5047 5036>,
			<6301 5671 5321 5097 5048 5036>,
			<6290 5663 5318 5098 5050 5037>,
			<6284 5656 5316 5100 5052 5039>,
			<6290 5648 5316 5102 5053 5040>,
			<6301 5642 5315 5104 5055 5041>,
			<6300 5649 5317 5108 5058 5043>,
			<6273 5682 5323 5112 5061 5045>,
			<6234 5700 5329 5117 5064 5047>,
			<6187 5673 5334 5123 5067 5050>,
			<6132 5630 5338 5129 5071 5053>,
			<6100 5607 5335 5139 5078 5058>,
			<6083 5591 5323 5150 5088 5065>,
			<6069 5576 5308 5152 5091 5067>,
			<6054 5557 5283 5134 5083 5065>,
			<6039 5539 5258 5112 5072 5060>,
			<6036 5527 5247 5097 5060 5050>,
			<6048 5518 5239 5085 5046 5036>,
			<6066 5509 5235 5082 5042 5031>,
			<6089 5498 5233 5083 5042 5032>,
			<6122 5489 5231 5083 5043 5032>,
			<6158 5494 5230 5085 5044 5033>,
			<6198 5515 5228 5088 5048 5036>,
			<6240 5541 5227 5091 5052 5038>,
			<6287 5571 5223 5094 5056 5042>,
			<6336 5608 5220 5096 5060 5045>,
			<6387 5650 5225 5099 5061 5048>,
			<6439 5699 5237 5101 5063 5051>,
			<6490 5753 5252 5101 5062 5051>,
			<6539 5813 5271 5098 5057 5044>,
			<6587 5879 5294 5095 5052 5039>,
			<6630 5950 5318 5092 5050 5039>,
			<6669 6028 5344 5091 5049 5040>,
			<6702 6112 5375 5093 5049 5041>,
			<6728 6201 5413 5099 5052 5045>,
			<6749 6296 5455 5099 5050 5043>,
			<6788 6398 5501 5098 5043 5032>,
			<6852 6513 5548 5097 5040 5027>,
			<6944 6559 5580 5103 5049 5041>,
			<6989 6655 5646 5113 5061 5056>,
			<7098 6759 5720 5127 5077 5071>,
			<7261 6877 5833 5147 5091 5084>,
			<7543 7040 5982 5157 5092 5081>,
			<8270 7330 6172 5144 5060 5049>,
			<10847 8471 6505 5141 5058 5048>,
			<17736 13713 7188 5167 5069 5054>,
			<43894 47233 9421 5215 5092 5080>,
			<43894 47233 9421 5215 5092 5080>,
			<43894 47233 9421 5215 5092 5080>;
	};

};
